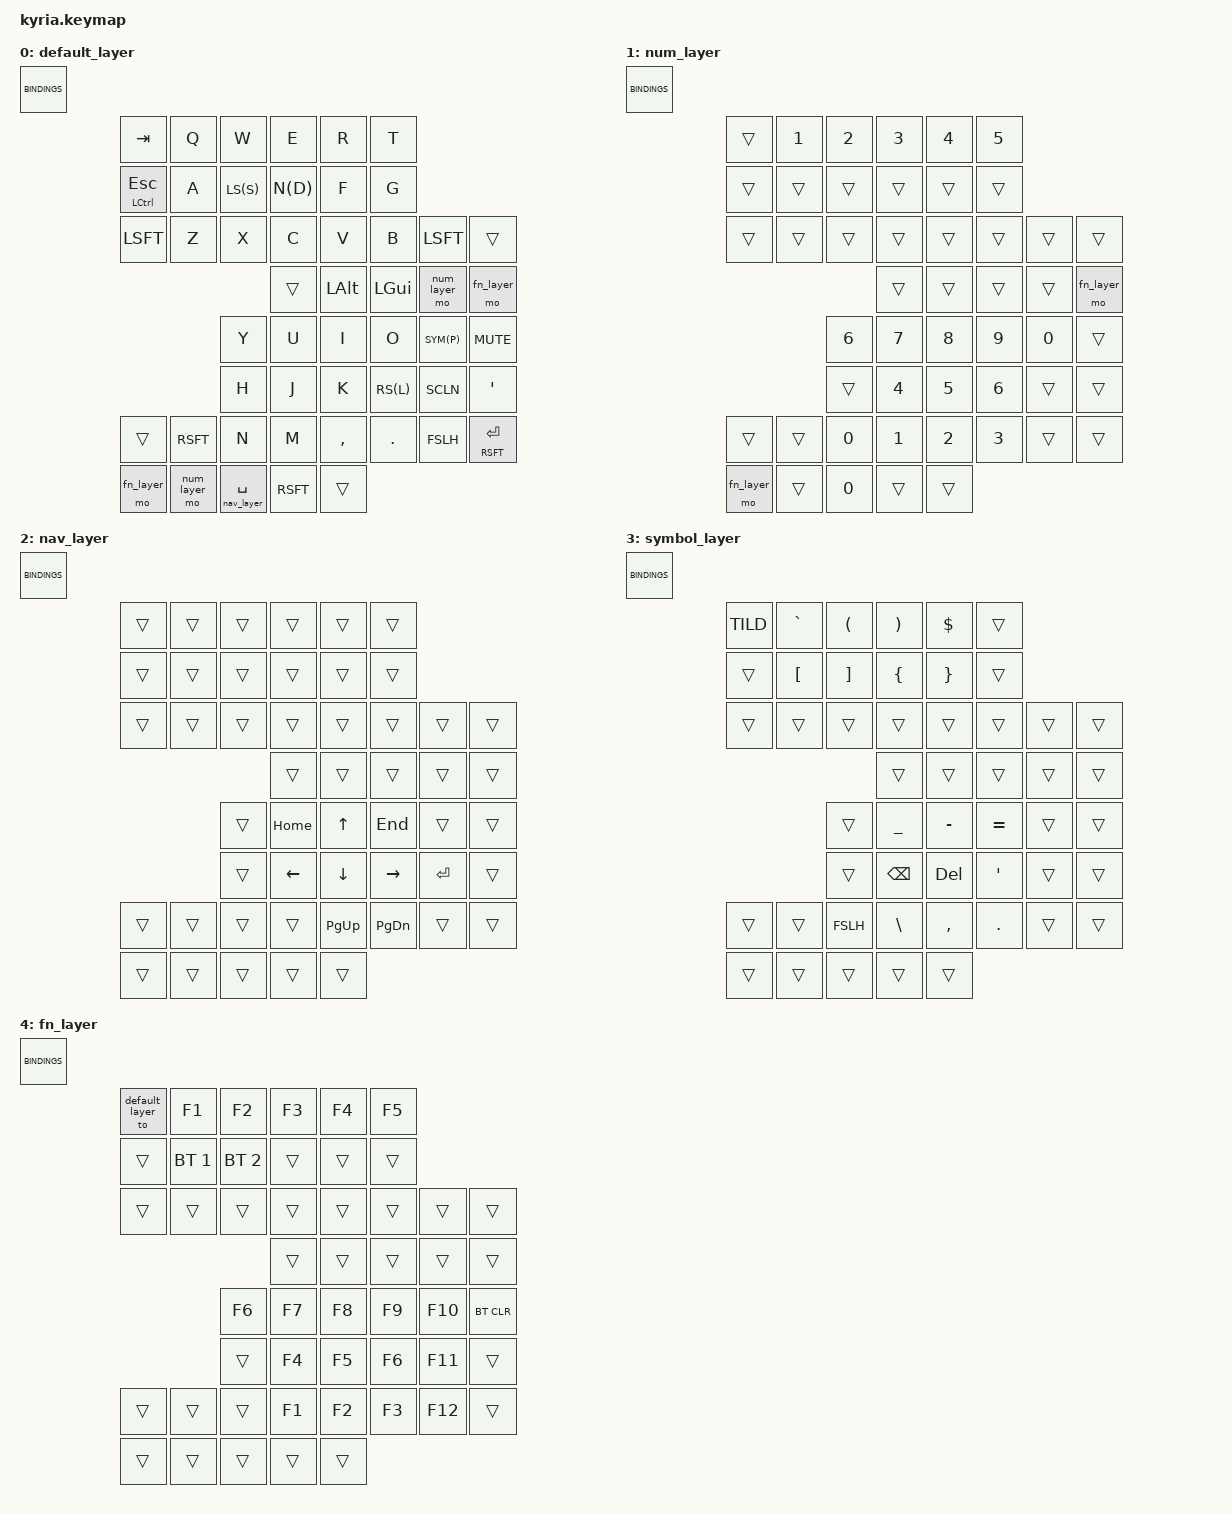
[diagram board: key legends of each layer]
/*
 * Copyright (c) 2020 The ZMK Contributors
 *
 * SPDX-License-Identifier: MIT
 */

#include <behaviors.dtsi>
#include <dt-bindings/zmk/keys.h>
#include <dt-bindings/zmk/bt.h>

#define _____   &trans
#define _BKSP   &kp BKSP
#define _BSLH   &kp BSLH
#define _CMMA   &kp CMMA
#define _DEL    &kp DEL
#define _DLLR   &kp DLLR
#define _DOT    &kp DOT
#define _EQL    &kp EQUAL
#define _ESC    &mt LCTL ESC
#define _FSLH   SYM(FSLH)
#define _GRAV   &kp GRAV
#define _LALS   &mt LALT SPC
#define _LALT   &kp LALT
#define _LBKT   &kp LBKT
#define _LBRC   &kp LBRC
#define _LCTL   &kp LCTL
#define _LGUS   &mt LGUI SPC
#define _LGUI   &kp LGUI
#define _LPAR   &kp LPAR
#define _LSFS   &mt LSFT SPC
#define _LSFT   &kp LSFT
#define _LS(x)  &mtp LSFT x
#define _MINS   &kp MINUS
#define _MUTE   &kp K_MUTE
#define _N(x)   &ltp num_layer x
#define _RALS   &mt RALT SPC
#define _RALT   &kp RALT
#define _RBKT   &kp RBKT
#define _RBRC   &kp RBRC
#define _RCTL   &kp RCTL
#define _RET    &kp RET
#define _RPAR   &kp RPAR
#define _RSFR   &mt RSFT RET
#define _RSFS   &mt RSFT SPC
#define _RSFT   &kp RSFT
#define _RS(x)  &mtp RSFT x
#define _SQT    &kp SQT
#define _TAB    &kp TAB
#define _TILD   &kp TILD
#define _UNDR   &kp UNDER

#define _LEFT   &kp LEFT
#define _DOWN   &kp DOWN
#define _UP     &kp UP
#define _RGHT   &kp RIGHT
#define _HOME   &kp HOME
#define _END    &kp END
#define _PGDN   &kp PG_DN
#define _PGUP   &kp PG_UP

#define _BT1    &bt BT_SEL 1
#define _BT2    &bt BT_SEL 2
#define _BTCLR  &bt BT_CLR

#define _F1     &kp F1
#define _F2     &kp F2
#define _F3     &kp F3
#define _F4     &kp F4
#define _F5     &kp F5
#define _F6     &kp F6
#define _F7     &kp F7
#define _F8     &kp F8
#define _F9     &kp F9
#define _F10    &kp F10
#define _F11    &kp F11
#define _F12    &kp F12

#define _N1     &kp N1
#define _N2     &kp N2
#define _N3     &kp N3
#define _N4     &kp N4
#define _N5     &kp N5
#define _N6     &kp N6
#define _N7     &kp N7
#define _N8     &kp N8
#define _N9     &kp N9
#define _N0     &kp N0


#define default_layer 0
#define _QWERTY &to default_layer

#define num_layer 1
#define _NUM &mo num_layer

#define nav_layer 2
#define _NAV &lt nav_layer SPC

#define symbol_layer 3
#define SYM(kp) &ltp symbol_layer kp
#define _SCLN   SYM(SCLN)

#define fn_layer 4
#define _FN &mo fn_layer

//#define colemak_layer 1
//#define COLEMAK &to colemak_layer

//#define plover_layer 2
//#define PLOVER &to plover_layer


#define TAPPING_TERM 200
#define BINDINGS(                            \
    k00, k01, k02, k03, k04, k05,            \
    k10, k11, k12, k13, k14, k15,            \
    k20, k21, k22, k23, k24, k25, k26, k27,  \
                   k33, k34, k35, k36, k37,  \
                                             \
              k0a, k0b, k0c, k0d, k0e, k0f,  \
              k1a, k1b, k1c, k1d, k1e, k1f,  \
    k28, k29, k2a, k2b, k2c, k2d, k2e, k2f,  \
    k38, k39, k3a, k3b, k3c)                 \
    \
    <k00 k01 k02 k03 k04 k05                 k0a k0b k0c k0d k0e k0f  \
     k10 k11 k12 k13 k14 k15                 k1a k1b k1c k1d k1e k1f  \
     k20 k21 k22 k23 k24 k25 k26 k27 k28 k29 k2a k2b k2c k2d k2e k2f  \
                 k33 k34 k35 k36 k37 k38 k39 k3a k3b k3c>


/ {

    behaviors {
        ltp: behavior_layer_tap_permissive {
            compatible = "zmk,behavior-hold-tap";
            label = "LAYER_TAP_PERMISSIVE";
            flavor = "balanced";
            tapping_term_ms = <TAPPING_TERM>;
            #binding-cells = <2>;
            bindings = <&mo>, <&kp>;
        };
        
        mtp: behavior_mod_tap_permissive {
            compatible = "zmk,behavior-hold-tap";
            label = "MOD_TAP_PERMISSIVE";
            tapping_term_ms = <TAPPING_TERM>;
            flavor = "balanced";
            #binding-cells = <2>;
            bindings = <&kp>, <&kp>;
        };
    };
};

/ {

    keymap {
        compatible = "zmk,keymap";

        default_layer {
            bindings = BINDINGS(
                _TAB,  &kp Q, &kp W, &kp E, &kp R, &kp T,
                _ESC,  &kp A, _LS(S),_N(D), &kp F, &kp G,
                _LSFT, &kp Z, &kp X, &kp C, &kp V, &kp B, _LSFT, _____,
                                     _____, _LALT, _LGUI, _NUM,  _FN,

                              &kp Y, &kp U, &kp I, &kp O, SYM(P),_MUTE,
                              &kp H, &kp J, &kp K, _RS(L),_SCLN, _SQT,
                _____, _RSFT, &kp N, &kp M, _CMMA, _DOT,  _FSLH, _RSFR,
                _FN,   _NUM,  _NAV, _RSFT, _____
            );
            sensor-bindings = <&inc_dec_kp UP DOWN &inc_dec_kp UP DOWN>;
        };

        num_layer {
            bindings = BINDINGS(
                _____, _N1,   _N2,   _N3,   _N4,   _N5,
                _____, _____, _____, _____, _____, _____,
                _____, _____, _____, _____, _____, _____, _____, _____,
                                     _____, _____, _____, _____, _FN,

                              _N6,   _N7,   _N8,   _N9,   _N0,   _____,
                              _____, _N4,   _N5,   _N6,   _____, _____,
                _____, _____, _N0,   _N1,   _N2,   _N3,   _____, _____,
                _FN,   _____, _N0,   _____, _____
            );
            sensor-bindings = <&inc_dec_kp UP DOWN &inc_dec_kp LEFT RIGHT>;
        };

        nav_layer {
            bindings = BINDINGS(
                _____, _____, _____, _____, _____, _____,
                _____, _____, _____, _____, _____, _____,
                _____, _____, _____, _____, _____, _____, _____, _____,
                                     _____, _____, _____, _____, _____,

                              _____, _HOME, _UP,   _END,  _____, _____,
                              _____, _LEFT, _DOWN, _RGHT, _RET,  _____,
                _____, _____, _____, _____, _PGUP, _PGDN, _____, _____,
                _____, _____, _____, _____, _____
            );
            sensor-bindings = <&inc_dec_kp UP DOWN &inc_dec_kp PG_UP PG_DN>;
        };

        symbol_layer {
            bindings = BINDINGS(
                _TILD, _GRAV, _LPAR, _RPAR, _DLLR, _____,
                _____, _LBKT, _RBKT, _LBRC, _RBRC, _____,
                _____, _____, _____, _____, _____, _____, _____, _____,
                                     _____, _____, _____, _____, _____,
                               
                              _____, _UNDR, _MINS, _EQL,  _____, _____,
                              _____, _BKSP, _DEL,  _SQT,  _____, _____,
                _____, _____, _FSLH, _BSLH, _CMMA, _DOT,  _____, _____,
                _____, _____, _____, _____, _____
            );
            sensor-bindings = <&inc_dec_kp UP DOWN &inc_dec_kp UP DOWN>;
        };

        fn_layer {
            bindings = BINDINGS(
                _QWERTY, _F1,   _F2,   _F3,   _F4,   _F5,
                _____,   _BT1,  _BT2,  _____, _____, _____,
                _____,   _____, _____, _____, _____, _____, _____, _____,
                                       _____, _____, _____, _____, _____,

                                _F6,   _F7,   _F8,   _F9,   _F10,  _BTCLR,
                                _____, _F4,   _F5,   _F6,   _F11,  _____,
                _____,   _____, _____, _F1,   _F2,   _F3,   _F12,  _____,
                _____,   _____, _____, _____, _____
            );
            sensor-bindings = <&inc_dec_kp UP DOWN &inc_dec_kp C_VOL_UP C_VOL_DN>;
        };

    };
};
